[part 1 of 3: package /ARRoot]
AUTOSAR XML (schema 3.1.1)
standard types defined: boolean, uint16, uint8, UInt8, Boolean, UInt16, UInt32
package /ARRoot
  ecu ECM_BODY_ECUType
  ecu instance ECM_BODY: associated-i-pdu-group=[IPDUGroupIN_CAN_HS_BACKBONE, IPDUGroupOUT_CAN_HS_BACKBONE, IPDUGroupIN_CAN_LS_BODY, IPDUGroupOUT_CAN_LS_BODY, IPDUGroupOUT_LIN_UPE_BODY], com-configuration-id=30, com-processing-period=0.01, diagnostic-address=32, pdu-r-configuration-id=31
    can communication controller ctl_CAN_HS_BACKBONE: number-of-samples=0, propagation-delay=0.0, sync-jump-width=0, time-seg-0=3, time-seg-1=1
    can communication controller ctl_CAN_LS_BODY: number-of-samples=0, propagation-delay=0.0, time-seg-0=3, time-seg-1=1
    lin slave ctl_LIN_UPE_BODY
    communication connector cc_CAN_HS_BACKBONE: channel=CAN_HS_BACKBONE, comm-controller=ctl_CAN_HS_BACKBONE
    communication connector cc_CAN_LS_BODY: channel=CAN_LS_BODY, comm-controller=ctl_CAN_LS_BODY
    communication connector cc_LIN_UPE_BODY: channel=LIN_UPE_BODY, comm-controller=ctl_LIN_UPE_BODY
  can cluster CAN_HS_BACKBONE_CANBus: protocol-name=CAN, speed=500000
    physical channel CAN_HS_BACKBONE
      frame BB_BODY_432: id 0x432, from ECM_BODY, frame-length=6, can-addressing-mode=STANDARD
        pdu ipdu_BB_BODY_432: length=48, cyclic-timing={repeating-time=0.05, starting-time=0.05}
          signal i_REVEIL_PRINCIPAL_N1: start 6, 2 bit, little-endian, data-type=t_REVEIL_PRINCIPAL, init-value=init_REVEIL_PRINCIPAL, update-indication-bit-position=6
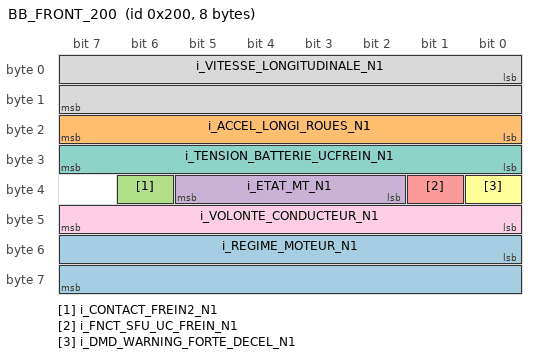
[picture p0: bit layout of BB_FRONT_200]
      frame BB_FRONT_200: id 0x200, to ECM_BODY, frame-length=8, can-addressing-mode=STANDARD
        pdu ipdu_BB_FRONT_200: length=64, cyclic-timing={repeating-time=0.01, starting-time=0.01}
          signal i_REGIME_MOTEUR_N1: start 48, 16 bit, little-endian, data-type=t_REGIME_MOTEUR, init-value=init_REGIME_MOTEUR, update-indication-bit-position=48, to ECM_BODY
          signal i_ACCEL_LONGI_ROUES_N1: start 16, 8 bit, little-endian, data-type=t_ACCEL_LONGI_ROUES, init-value=init_ACCEL_LONGI_ROUES, update-indication-bit-position=16, to ECM_BODY
          signal i_CONTACT_FREIN2_N1: start 38, 1 bit, little-endian, data-type=ARRoot/boolean, init-value=init_CONTACT_FREIN2, update-indication-bit-position=38, to ECM_BODY
          signal i_ETAT_MT_N1: start 34, 4 bit, little-endian, data-type=uint4, init-value=init_ETAT_MT, update-indication-bit-position=34, to ECM_BODY
          signal i_FNCT_SFU_UC_FREIN_N1: start 33, 1 bit, little-endian, data-type=ARRoot/boolean, init-value=init_FNCT_SFU_UC_FREIN, update-indication-bit-position=33, to ECM_BODY
          signal i_DMD_WARNING_FORTE_DECEL_N1: start 32, 1 bit, little-endian, data-type=ARRoot/boolean, init-value=init_DMD_WARNING_FORTE_DECEL, update-indication-bit-position=32, to ECM_BODY
          signal i_TENSION_BATTERIE_UCFREIN_N1: start 24, 8 bit, little-endian, data-type=t_TENSION_BATTERIE_UCFREIN, init-value=init_TENSION_BATTERIE_UCFREIN, update-indication-bit-position=24, to ECM_BODY
          signal i_VITESSE_LONGITUDINALE_N1: start 0, 16 bit, little-endian, data-type=t_VITESSE_LONGITUDINALE, init-value=init_VITESSE_LONGITUDINALE, update-indication-bit-position=0, to ECM_BODY
          signal i_VOLONTE_CONDUCTEUR_N1: start 40, 8 bit, little-endian, data-type=t_VOLONTE_CONDUCTEUR, init-value=init_VOLONTE_CONDUCTEUR, update-indication-bit-position=40, to ECM_BODY
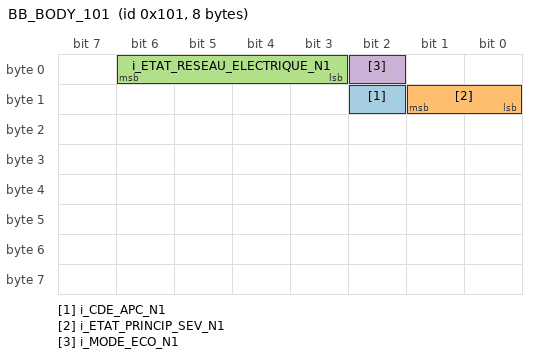
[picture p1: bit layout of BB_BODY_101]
      frame BB_BODY_101: id 0x101, from ECM_BODY, frame-length=8, can-addressing-mode=STANDARD
        pdu ipdu_BB_BODY_101: length=64, cyclic-timing={repeating-time=0.05, starting-time=0.05}
          signal i_CDE_APC_N1: start 10, 1 bit, little-endian, data-type=ARRoot/boolean, init-value=init_CDE_APC, update-indication-bit-position=10
          signal i_ETAT_PRINCIP_SEV_N1: start 8, 2 bit, little-endian, data-type=t_ETAT_PRINCIP_SEV, init-value=init_ETAT_PRINCIP_SEV, update-indication-bit-position=8
          signal i_ETAT_RESEAU_ELECTRIQUE_N1: start 3, 4 bit, little-endian, data-type=t_ETAT_RESEAU_ELECTRIQUE, init-value=init_ETAT_RESEAU_ELECTRIQUE, update-indication-bit-position=3
          signal i_MODE_ECO_N1: start 2, 1 bit, little-endian, data-type=ARRoot/boolean, init-value=init_MODE_ECO, update-indication-bit-position=2
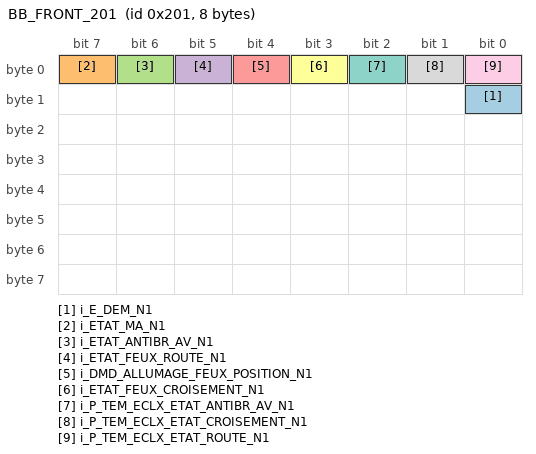
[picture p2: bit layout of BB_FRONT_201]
      frame BB_FRONT_201: id 0x201, to ECM_BODY, frame-length=8, can-addressing-mode=STANDARD
        pdu ipdu_BB_FRONT_201: length=64, cyclic-timing={repeating-time=0.05, starting-time=0.05}
          signal i_E_DEM_N1: start 8, 1 bit, little-endian, data-type=ARRoot/boolean, init-value=init_E_DEM, update-indication-bit-position=8, to ECM_BODY
          signal i_ETAT_MA_N1: start 7, 1 bit, little-endian, data-type=ARRoot/boolean, init-value=init_ETAT_MA, update-indication-bit-position=7, to ECM_BODY
          signal i_ETAT_ANTIBR_AV_N1: start 6, 1 bit, little-endian, data-type=ARRoot/boolean, init-value=init_ETAT_ANTIBR_AV, update-indication-bit-position=6, to ECM_BODY
          signal i_ETAT_FEUX_ROUTE_N1: start 5, 1 bit, little-endian, data-type=ARRoot/boolean, init-value=init_ETAT_FEUX_ROUTE, update-indication-bit-position=5, to ECM_BODY
          signal i_DMD_ALLUMAGE_FEUX_POSITION_N1: start 4, 1 bit, little-endian, data-type=ARRoot/boolean, init-value=init_DMD_ALLUMAGE_FEUX_POSITION, update-indication-bit-position=4, to ECM_BODY
          signal i_ETAT_FEUX_CROISEMENT_N1: start 3, 1 bit, little-endian, data-type=ARRoot/boolean, init-value=init_ETAT_FEUX_CROISEMENT, update-indication-bit-position=3, to ECM_BODY
          signal i_P_TEM_ECLX_ETAT_ANTIBR_AV_N1: start 2, 1 bit, little-endian, data-type=ARRoot/boolean, init-value=init_P_TEM_ECLX_ETAT_ANTIBR_AV, update-indication-bit-position=2, to ECM_BODY
          signal i_P_TEM_ECLX_ETAT_CROISEMENT_N1: start 1, 1 bit, little-endian, data-type=ARRoot/boolean, init-value=init_P_TEM_ECLX_ETAT_CROISEMENT, update-indication-bit-position=1, to ECM_BODY
          signal i_P_TEM_ECLX_ETAT_ROUTE_N1: start 0, 1 bit, little-endian, data-type=ARRoot/boolean, init-value=init_P_TEM_ECLX_ETAT_ROUTE, update-indication-bit-position=0, to ECM_BODY
      frame BB_BODY_100: id 0x100, from ECM_BODY, frame-length=8, can-addressing-mode=STANDARD
        pdu ipdu_BB_BODY_100: length=64, cyclic-timing={repeating-time=0.05, starting-time=0.05}
          signal i_PILOTAGE_FEUX_POSITION_AVG_N1: start 22, 1 bit, little-endian, data-type=ARRoot/boolean, init-value=init_PILOTAGE_FEUX_POSITION_AVG, update-indication-bit-position=22
          signal i_PILOTAGE_FEUX_POSITION_AVD_N1: start 23, 1 bit, little-endian, data-type=ARRoot/boolean, init-value=init_PILOTAGE_FEUX_POSITION_AVD, update-indication-bit-position=23
          signal i_CMD_FEUX_POSITION_AR_N1: start 21, 1 bit, little-endian, data-type=ARRoot/boolean, init-value=init_CMD_FEUX_POSITION_AR, update-indication-bit-position=21
          signal i_TYPE_REVEIL_BAGUE_ECLAIRAGE_N1: start 20, 1 bit, little-endian, data-type=ARRoot/boolean, init-value=init_TYPE_REVEIL_BAGUE_ECLAIRAGE, update-indication-bit-position=20
          signal i_CMD_FEUX_STOP_N1: start 19, 1 bit, little-endian, data-type=ARRoot/boolean, init-value=init_CMD_FEUX_STOP, update-indication-bit-position=19
          signal i_CMD_FEUX_MAR_N1: start 18, 1 bit, little-endian, data-type=ARRoot/boolean, init-value=init_CMD_FEUX_MAR, update-indication-bit-position=18
          signal i_CMD_ANTIBR_AR_N1: start 17, 1 bit, little-endian, data-type=ARRoot/boolean, init-value=init_CMD_ANTIBR_AR, update-indication-bit-position=17
          signal i_PILOTAGE_FEU_DIURNE_DEDIE_G_N1: start 16, 1 bit, little-endian, data-type=ARRoot/boolean, init-value=init_PILOTAGE_FEU_DIURNE_DEDIE_G, update-indication-bit-position=16
          signal i_PILOTAGE_FEU_DIURNE_DEDIE_D_N1: start 15, 1 bit, little-endian, data-type=ARRoot/boolean, init-value=init_PILOTAGE_FEU_DIURNE_DEDIE_D, update-indication-bit-position=15
          signal i_CMD_AVER_SONORE_N1: start 14, 1 bit, little-endian, data-type=ARRoot/boolean, init-value=init_CMD_AVER_SONORE, update-indication-bit-position=14
          signal DMD_ANTIBROUILLARD0_IS: start 11, 2 bit, little-endian, data-type=t_DMD_ANTIBROUILLARD, init-value=init_DMD_ANTIBROUILLARD, update-indication-bit-position=11
          signal i_DMD_FEUX_CROISEMENT_AAF_N1: start 10, 1 bit, little-endian, data-type=ARRoot/boolean, init-value=init_DMD_FEUX_CROISEMENT_AAF, update-indication-bit-position=10
          signal i_DMD_ALLUMAGE_FEUX_CROISEMENT_N1: start 9, 1 bit, little-endian, data-type=ARRoot/boolean, init-value=init_DMD_ALLUMAGE_FEUX_CROISEMENT, update-indication-bit-position=9
          signal i_DMD_LOCAL_TELECMD_N1: start 8, 1 bit, little-endian, data-type=ARRoot/boolean, init-value=init_DMD_LOCAL_TELECMD, update-indication-bit-position=8
          signal i_ETAT_ANTIBR_AR_N1: start 7, 1 bit, little-endian, data-type=ARRoot/boolean, init-value=init_ETAT_ANTIBR_AR, update-indication-bit-position=7
          signal i_ETAT_FEUX_DIURNES_N1: start 6, 1 bit, little-endian, data-type=ARRoot/boolean, init-value=init_ETAT_FEUX_DIURNES, update-indication-bit-position=6
          signal i_ETAT_FEUX_POSITION_N1: start 5, 1 bit, little-endian, data-type=ARRoot/boolean, init-value=init_ETAT_FEUX_POSITION, update-indication-bit-position=5
          signal i_ETAT_CMD_ECLAIRAGE_N1: start 0, 4 bit, little-endian, data-type=t_ETAT_CMD_ECLAIRAGE, init-value=init_ETAT_CMD_ECLAIRAGE, update-indication-bit-position=0
  integer type t_REVEIL_PRINCIPAL: lower-limit=0, upper-limit=3
  constant specification cst_init_REVEIL_PRINCIPAL
    value:
      integer literal init_REVEIL_PRINCIPAL: type=t_REVEIL_PRINCIPAL, value=0
  integer type t_REGIME_MOTEUR: lower-limit=0, upper-limit=65534
  constant specification cst_init_REGIME_MOTEUR
    value:
      integer literal init_REGIME_MOTEUR: type=t_REGIME_MOTEUR, value=0
  integer type t_ACCEL_LONGI_ROUES: lower-limit=0, upper-limit=254
  constant specification cst_init_ACCEL_LONGI_ROUES
    value:
      integer literal init_ACCEL_LONGI_ROUES: type=t_ACCEL_LONGI_ROUES, value=0
  constant specification cst_init_CONTACT_FREIN2
    value:
      boolean literal init_CONTACT_FREIN2: type=ARRoot/boolean, value=false
  integer type uint4: lower-limit=0, upper-limit=16
  constant specification cst_init_ETAT_MT
    value:
      integer literal init_ETAT_MT: type=uint4, value=0
  constant specification cst_init_FNCT_SFU_UC_FREIN
    value:
      boolean literal init_FNCT_SFU_UC_FREIN: type=ARRoot/boolean, value=false
  constant specification cst_init_DMD_WARNING_FORTE_DECEL
    value:
      boolean literal init_DMD_WARNING_FORTE_DECEL: type=ARRoot/boolean, value=false
  integer type t_TENSION_BATTERIE_UCFREIN: lower-limit=0, upper-limit=230
  constant specification cst_init_TENSION_BATTERIE_UCFREIN
    value:
      integer literal init_TENSION_BATTERIE_UCFREIN: type=t_TENSION_BATTERIE_UCFREIN, value=0
  integer type t_VITESSE_LONGITUDINALE: lower-limit=0, upper-limit=65534
  constant specification cst_init_VITESSE_LONGITUDINALE
    value:
      integer literal init_VITESSE_LONGITUDINALE: type=t_VITESSE_LONGITUDINALE, value=0
  integer type t_VOLONTE_CONDUCTEUR: lower-limit=0, upper-limit=100
  constant specification cst_init_VOLONTE_CONDUCTEUR
    value:
      integer literal init_VOLONTE_CONDUCTEUR: type=t_VOLONTE_CONDUCTEUR, value=0
  constant specification cst_init_CDE_APC
    value:
      boolean literal init_CDE_APC: type=ARRoot/boolean, value=false
  integer type t_ETAT_PRINCIP_SEV: lower-limit=0, upper-limit=2
  constant specification cst_init_ETAT_PRINCIP_SEV
    value:
      integer literal init_ETAT_PRINCIP_SEV: type=t_ETAT_PRINCIP_SEV, value=0
  integer type t_ETAT_RESEAU_ELECTRIQUE: lower-limit=0, upper-limit=8
  constant specification cst_init_ETAT_RESEAU_ELECTRIQUE
    value:
      integer literal init_ETAT_RESEAU_ELECTRIQUE: type=t_ETAT_RESEAU_ELECTRIQUE, value=0
  constant specification cst_init_MODE_ECO
    value:
      boolean literal init_MODE_ECO: type=ARRoot/boolean, value=false
  constant specification cst_init_E_DEM
    value:
      boolean literal init_E_DEM: type=ARRoot/boolean, value=false
  constant specification cst_init_ETAT_MA
    value:
      boolean literal init_ETAT_MA: type=ARRoot/boolean, value=false
  constant specification cst_init_ETAT_ANTIBR_AV
    value:
      boolean literal init_ETAT_ANTIBR_AV: type=ARRoot/boolean, value=false
  constant specification cst_init_ETAT_FEUX_ROUTE
    value:
      boolean literal init_ETAT_FEUX_ROUTE: type=ARRoot/boolean, value=false
  constant specification cst_init_DMD_ALLUMAGE_FEUX_POSITION
    value:
      boolean literal init_DMD_ALLUMAGE_FEUX_POSITION: type=ARRoot/boolean, value=false
  constant specification cst_init_ETAT_FEUX_CROISEMENT
    value:
      boolean literal init_ETAT_FEUX_CROISEMENT: type=ARRoot/boolean, value=false
  constant specification cst_init_P_TEM_ECLX_ETAT_ANTIBR_AV
    value:
      boolean literal init_P_TEM_ECLX_ETAT_ANTIBR_AV: type=ARRoot/boolean, value=false
  constant specification cst_init_P_TEM_ECLX_ETAT_CROISEMENT
    value:
      boolean literal init_P_TEM_ECLX_ETAT_CROISEMENT: type=ARRoot/boolean, value=false
  constant specification cst_init_P_TEM_ECLX_ETAT_ROUTE
    value:
      boolean literal init_P_TEM_ECLX_ETAT_ROUTE: type=ARRoot/boolean, value=false
  constant specification cst_init_PILOTAGE_FEUX_POSITION_AVG
    value:
      boolean literal init_PILOTAGE_FEUX_POSITION_AVG: type=ARRoot/boolean, value=false
  constant specification cst_init_PILOTAGE_FEUX_POSITION_AVD
    value:
      boolean literal init_PILOTAGE_FEUX_POSITION_AVD: type=ARRoot/boolean, value=false
  constant specification cst_init_CMD_FEUX_POSITION_AR
    value:
      boolean literal init_CMD_FEUX_POSITION_AR: type=ARRoot/boolean, value=false
  constant specification cst_init_TYPE_REVEIL_BAGUE_ECLAIRAGE
    value:
      boolean literal init_TYPE_REVEIL_BAGUE_ECLAIRAGE: type=ARRoot/boolean, value=false
  constant specification cst_init_CMD_FEUX_STOP
    value:
      boolean literal init_CMD_FEUX_STOP: type=ARRoot/boolean, value=false
  constant specification cst_init_CMD_FEUX_MAR
    value:
      boolean literal init_CMD_FEUX_MAR: type=ARRoot/boolean, value=false
  constant specification cst_init_CMD_ANTIBR_AR
    value:
      boolean literal init_CMD_ANTIBR_AR: type=ARRoot/boolean, value=false
  constant specification cst_init_PILOTAGE_FEU_DIURNE_DEDIE_G
    value:
      boolean literal init_PILOTAGE_FEU_DIURNE_DEDIE_G: type=ARRoot/boolean, value=false
  constant specification cst_init_PILOTAGE_FEU_DIURNE_DEDIE_D
    value:
      boolean literal init_PILOTAGE_FEU_DIURNE_DEDIE_D: type=ARRoot/boolean, value=false
  constant specification cst_init_CMD_AVER_SONORE
    value:
      boolean literal init_CMD_AVER_SONORE: type=ARRoot/boolean, value=false
  integer type t_DMD_ANTIBROUILLARD: lower-limit=0, upper-limit=2
  constant specification cst_init_DMD_ANTIBROUILLARD
    value:
      integer literal init_DMD_ANTIBROUILLARD: type=t_DMD_ANTIBROUILLARD, value=0
  constant specification cst_init_DMD_FEUX_CROISEMENT_AAF
    value:
      boolean literal init_DMD_FEUX_CROISEMENT_AAF: type=ARRoot/boolean, value=false
  constant specification cst_init_DMD_ALLUMAGE_FEUX_CROISEMENT
    value:
      boolean literal init_DMD_ALLUMAGE_FEUX_CROISEMENT: type=ARRoot/boolean, value=false
  constant specification cst_init_DMD_LOCAL_TELECMD
    value:
      boolean literal init_DMD_LOCAL_TELECMD: type=ARRoot/boolean, value=false
  constant specification cst_init_ETAT_ANTIBR_AR
    value:
      boolean literal init_ETAT_ANTIBR_AR: type=ARRoot/boolean, value=false
  constant specification cst_init_ETAT_FEUX_DIURNES
    value:
      boolean literal init_ETAT_FEUX_DIURNES: type=ARRoot/boolean, value=false
  constant specification cst_init_ETAT_FEUX_POSITION
    value:
      boolean literal init_ETAT_FEUX_POSITION: type=ARRoot/boolean, value=false
  integer type t_ETAT_CMD_ECLAIRAGE: lower-limit=0, upper-limit=8
  constant specification cst_init_ETAT_CMD_ECLAIRAGE
    value:
      integer literal init_ETAT_CMD_ECLAIRAGE: type=t_ETAT_CMD_ECLAIRAGE, value=0
  can cluster CAN_LS_BODY_CANBus: protocol-name=CAN, speed=125000
    physical channel CAN_LS_BODY
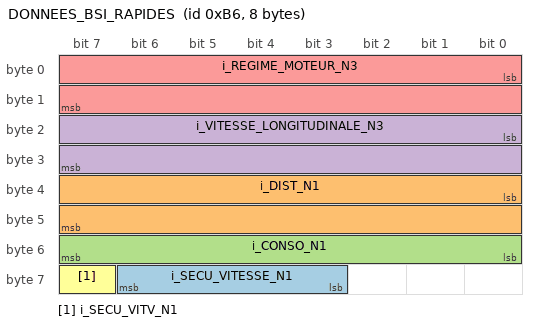
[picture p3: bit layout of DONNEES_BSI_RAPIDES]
      frame DONNEES_BSI_RAPIDES: id 0xB6, from ECM_BODY, frame-length=8, can-addressing-mode=STANDARD
        pdu ipdu_DONNEES_BSI_RAPIDES: length=64, cyclic-timing={repeating-time=0.05, starting-time=0.05}
          signal i_SECU_VITESSE_N1: start 59, 4 bit, little-endian, data-type=uint4, init-value=init_SECU_VITESSE, update-indication-bit-position=59
          signal i_DIST_N1: start 32, 16 bit, little-endian, data-type=uint16, init-value=init_DIST, update-indication-bit-position=32
          signal i_CONSO_N1: start 48, 8 bit, little-endian, data-type=uint8, init-value=init_CONSO, update-indication-bit-position=48
          signal i_VITESSE_LONGITUDINALE_N3: start 16, 16 bit, little-endian, data-type=t_VITESSE_LONGITUDINALE, init-value=init_VITESSE_LONGITUDINALE, update-indication-bit-position=16
          signal i_REGIME_MOTEUR_N3: start 0, 16 bit, little-endian, data-type=t_REGIME_MOTEUR, init-value=init_REGIME_MOTEUR, update-indication-bit-position=0
          signal i_SECU_VITV_N1: start 63, 1 bit, little-endian, data-type=ARRoot/boolean, init-value=init_SECU_VITV, update-indication-bit-position=63
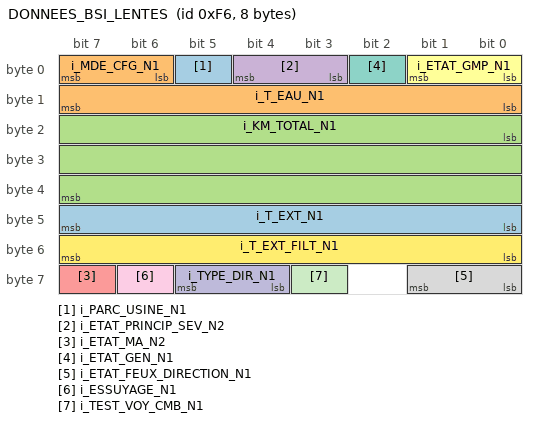
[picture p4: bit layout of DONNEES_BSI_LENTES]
      frame DONNEES_BSI_LENTES: id 0xF6, from ECM_BODY, frame-length=8, can-addressing-mode=STANDARD
        pdu ipdu_DONNEES_BSI_LENTES: length=64, cyclic-timing={repeating-time=0.5, starting-time=0.5}
          signal i_PARC_USINE_N1: start 5, 1 bit, little-endian, data-type=ARRoot/boolean, init-value=init_PARC_USINE, update-indication-bit-position=5
          signal i_MDE_CFG_N1: start 6, 2 bit, little-endian, data-type=uint2, init-value=init_MDE_CFG, update-indication-bit-position=6
          signal i_KM_TOTAL_N1: start 16, 24 bit, little-endian, data-type=t_KM_TOTAL, init-value=init_KM_TOTAL, update-indication-bit-position=16
          signal i_ETAT_PRINCIP_SEV_N2: start 3, 2 bit, little-endian, data-type=t_ETAT_PRINCIP_SEV, init-value=init_ETAT_PRINCIP_SEV, update-indication-bit-position=3
          signal i_ETAT_MA_N2: start 63, 1 bit, little-endian, data-type=ARRoot/boolean, init-value=init_ETAT_MA, update-indication-bit-position=63
          signal i_ETAT_GMP_N1: start 0, 2 bit, little-endian, data-type=uint2, init-value=init_ETAT_GMP, update-indication-bit-position=0
          signal i_ETAT_GEN_N1: start 2, 1 bit, little-endian, data-type=ARRoot/boolean, init-value=init_ETAT_GEN, update-indication-bit-position=2
          signal i_ETAT_FEUX_DIRECTION_N1: start 56, 2 bit, little-endian, data-type=uint2, init-value=init_ETAT_FEUX_DIRECTION, update-indication-bit-position=56
          signal i_ESSUYAGE_N1: start 62, 1 bit, little-endian, data-type=ARRoot/boolean, init-value=init_ESSUYAGE, update-indication-bit-position=62
          signal i_TYPE_DIR_N1: start 60, 2 bit, little-endian, data-type=uint2, init-value=init_TYPE_DIR, update-indication-bit-position=60
          signal i_TEST_VOY_CMB_N1: start 59, 1 bit, little-endian, data-type=ARRoot/boolean, init-value=init_TEST_VOY_CMB, update-indication-bit-position=59
          signal i_T_EXT_FILT_N1: start 48, 8 bit, little-endian, data-type=t_T_EXT_FILT, init-value=init_T_EXT_FILT, update-indication-bit-position=48
          signal i_T_EXT_N1: start 40, 8 bit, little-endian, data-type=t_T_EXT, init-value=init_T_EXT, update-indication-bit-position=40
          signal i_T_EAU_N1: start 8, 8 bit, little-endian, data-type=t_T_EAU, init-value=init_T_EAU, update-indication-bit-position=8
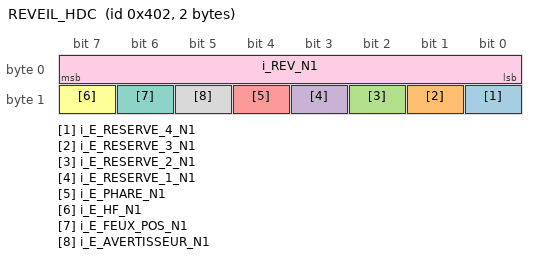
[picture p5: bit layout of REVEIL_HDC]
      frame REVEIL_HDC: id 0x402, to ECM_BODY, frame-length=2, can-addressing-mode=STANDARD
        pdu ipdu_REVEIL_HDC: length=16, cyclic-timing={repeating-time=0.01, starting-time=0.01}, event-controlled-timing=debounce-time=0.0
          signal i_E_RESERVE_4_N1: start 8, 1 bit, little-endian, data-type=ARRoot/boolean, init-value=init_E_RESERVE_4, update-indication-bit-position=8, to ECM_BODY
          signal i_E_RESERVE_3_N1: start 9, 1 bit, little-endian, data-type=ARRoot/boolean, init-value=init_E_RESERVE_3, update-indication-bit-position=9, to ECM_BODY
          signal i_E_RESERVE_2_N1: start 10, 1 bit, little-endian, data-type=ARRoot/boolean, init-value=init_E_RESERVE_2, update-indication-bit-position=10, to ECM_BODY
          signal i_E_RESERVE_1_N1: start 11, 1 bit, little-endian, data-type=ARRoot/boolean, init-value=init_E_RESERVE_1, update-indication-bit-position=11, to ECM_BODY
          signal i_E_PHARE_N1: start 12, 1 bit, little-endian, data-type=ARRoot/boolean, init-value=init_E_PHARE, update-indication-bit-position=12, to ECM_BODY
          signal i_E_HF_N1: start 15, 1 bit, little-endian, data-type=ARRoot/boolean, init-value=init_E_HF, update-indication-bit-position=15, to ECM_BODY
          signal i_E_FEUX_POS_N1: start 14, 1 bit, little-endian, data-type=ARRoot/boolean, init-value=init_E_FEUX_POS, update-indication-bit-position=14, to ECM_BODY
          signal i_E_AVERTISSEUR_N1: start 13, 1 bit, little-endian, data-type=ARRoot/boolean, init-value=init_E_AVERTISSEUR, update-indication-bit-position=13, to ECM_BODY
          signal i_REV_N1: start 0, 8 bit, little-endian, data-type=uint8, init-value=init_REV, update-indication-bit-position=0, to ECM_BODY
      frame COMMANDE_BRT: id 0x102, from ECM_BODY, frame-length=2, can-addressing-mode=STANDARD
        pdu ipdu_COMMANDE_BRT: length=16, event-controlled-timing=debounce-time=0.0
          signal i_NIV_SON_CMD_BRT_N1: start 8, 8 bit, little-endian, data-type=t_NIV_SON_CMD_BRT, init-value=init_NIV_SON_CMD_BRT, update-indication-bit-position=8
          signal i_EM_SON_CMD_BRT_N1: start 0, 4 bit, little-endian, data-type=t_EM_SON_CMD_BRT, init-value=init_EM_SON_CMD_BRT, update-indication-bit-position=0
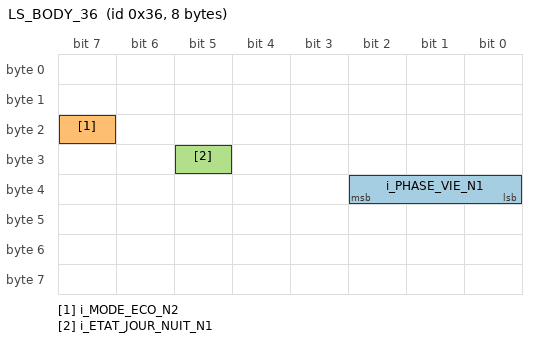
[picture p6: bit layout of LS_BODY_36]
      frame LS_BODY_36: id 0x36, from ECM_BODY, frame-length=8, can-addressing-mode=STANDARD
        pdu ipdu_LS_BODY_36: length=64, cyclic-timing={repeating-time=0.1, starting-time=0.1}, event-controlled-timing=debounce-time=0.0
          signal i_PHASE_VIE_N1: start 32, 3 bit, little-endian, data-type=t_PHASE_VIE, init-value=init_PHASE_VIE, update-indication-bit-position=32
          signal i_MODE_ECO_N2: start 23, 1 bit, little-endian, data-type=ARRoot/boolean, init-value=init_MODE_ECO, update-indication-bit-position=23
          signal i_ETAT_JOUR_NUIT_N1: start 29, 1 bit, little-endian, data-type=ARRoot/boolean, init-value=init_ETAT_JOUR_NUIT, update-indication-bit-position=29
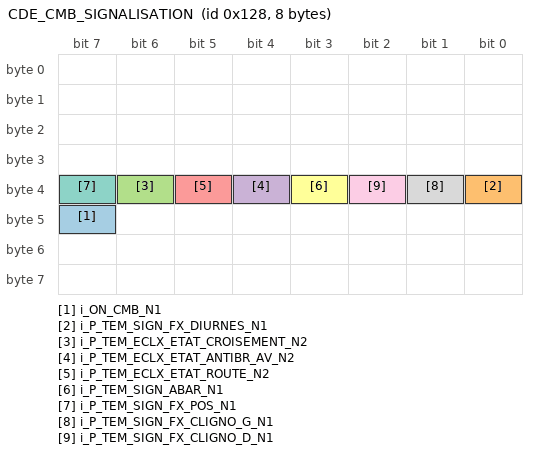
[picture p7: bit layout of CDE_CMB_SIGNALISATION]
      frame CDE_CMB_SIGNALISATION: id 0x128, from ECM_BODY, frame-length=8, can-addressing-mode=STANDARD
        pdu ipdu_CDE_CMB_SIGNALISATION: length=64, cyclic-timing={repeating-time=0.2, starting-time=0.2}, event-controlled-timing=debounce-time=0.0
          signal i_ON_CMB_N1: start 47, 1 bit, little-endian, data-type=ARRoot/boolean, init-value=init_ON_CMB, update-indication-bit-position=47
          signal i_P_TEM_SIGN_FX_DIURNES_N1: start 32, 1 bit, little-endian, data-type=ARRoot/boolean, init-value=init_P_TEM_SIGN_FX_DIURNES, update-indication-bit-position=32
          signal i_P_TEM_ECLX_ETAT_CROISEMENT_N2: start 38, 1 bit, little-endian, data-type=ARRoot/boolean, init-value=init_P_TEM_ECLX_ETAT_CROISEMENT, update-indication-bit-position=38
          signal i_P_TEM_ECLX_ETAT_ANTIBR_AV_N2: start 36, 1 bit, little-endian, data-type=ARRoot/boolean, init-value=init_P_TEM_ECLX_ETAT_ANTIBR_AV, update-indication-bit-position=36
          signal i_P_TEM_ECLX_ETAT_ROUTE_N2: start 37, 1 bit, little-endian, data-type=ARRoot/boolean, init-value=init_P_TEM_ECLX_ETAT_ROUTE, update-indication-bit-position=37
          signal i_P_TEM_SIGN_ABAR_N1: start 35, 1 bit, little-endian, system signal P_TEM_SIGN_FX_ABAR, data-type=ARRoot/boolean, init-value=init_P_TEM_SIGN_ABAR, update-indication-bit-position=35
          signal i_P_TEM_SIGN_FX_POS_N1: start 39, 1 bit, little-endian, data-type=ARRoot/boolean, init-value=init_P_TEM_SIGN_FX_POS, update-indication-bit-position=39
          signal i_P_TEM_SIGN_FX_CLIGNO_G_N1: start 33, 1 bit, little-endian, data-type=ARRoot/boolean, init-value=init_P_TEM_SIGN_FX_CLIGNO_G, update-indication-bit-position=33
          signal i_P_TEM_SIGN_FX_CLIGNO_D_N1: start 34, 1 bit, little-endian, data-type=ARRoot/boolean, init-value=init_P_TEM_SIGN_FX_CLIGNO_D, update-indication-bit-position=34
      frame ETAT_BDCP: id 0x184, to ECM_BODY, frame-length=1, can-addressing-mode=STANDARD
        pdu ipdu_ETAT_BDCP: length=8, cyclic-timing={repeating-time=0.2, starting-time=0.2}, event-controlled-timing=debounce-time=0.0
          signal i_INFO_CHOC_PIETON_N1: start 4, 1 bit, little-endian, data-type=ARRoot/boolean, init-value=init_INFO_CHOC_PIETON, update-indication-bit-position=4, to ECM_BODY
          signal i_CHOC_FEUX_DET_N1: start 0, 1 bit, little-endian, data-type=ARRoot/boolean, init-value=init_CHOC_FEUX_DET, update-indication-bit-position=0, to ECM_BODY
      frame ETAT_CDPL_RAPIDES: id 0x5A, to ECM_BODY, frame-length=2, can-addressing-mode=STANDARD
        pdu ipdu_ETAT_CDPL_RAPIDES: length=16, cyclic-timing={repeating-time=0.1, starting-time=0.1}
          signal i_DMD_FEUX_CROISEMENT_AAF_N2: start 0, 1 bit, little-endian, data-type=ARRoot/boolean, init-value=init_DMD_FEUX_CROISEMENT_AAF, update-indication-bit-position=0, to ECM_BODY
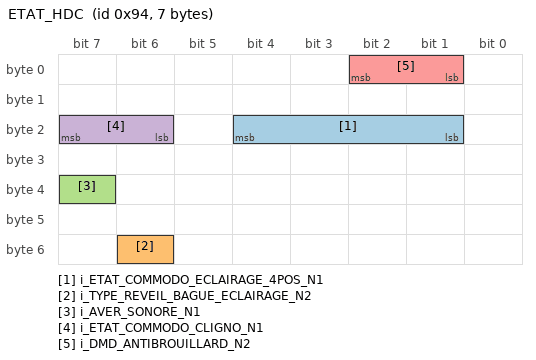
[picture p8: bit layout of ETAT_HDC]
      frame ETAT_HDC: id 0x94, to ECM_BODY, frame-length=7, can-addressing-mode=STANDARD
        pdu ipdu_ETAT_HDC: length=56, cyclic-timing={repeating-time=0.1, starting-time=0.1}, event-controlled-timing=debounce-time=0.0
          signal i_ETAT_COMMODO_ECLAIRAGE_4POS_N1: start 17, 4 bit, little-endian, data-type=t_ETAT_COMMODO_ECLAIRAGE_4POS, init-value=init_ETAT_COMMODO_ECLAIRAGE_4POS, update-indication-bit-position=17, to ECM_BODY
          signal i_TYPE_REVEIL_BAGUE_ECLAIRAGE_N2: start 54, 1 bit, little-endian, data-type=ARRoot/boolean, init-value=init_TYPE_REVEIL_BAGUE_ECLAIRAGE, update-indication-bit-position=54, to ECM_BODY
          signal i_AVER_SONORE_N1: start 39, 1 bit, little-endian, data-type=ARRoot/boolean, init-value=init_AVER_SONORE, update-indication-bit-position=39, to ECM_BODY
          signal i_ETAT_COMMODO_CLIGNO_N1: start 22, 2 bit, little-endian, data-type=t_ETAT_COMMODO_CLIGNO, init-value=init_ETAT_COMMODO_CLIGNO, update-indication-bit-position=22, to ECM_BODY
          signal i_DMD_ANTIBROUILLARD_N2: start 1, 2 bit, little-endian, system signal ETAT_DMD_ANTIBROUILLARD, data-type=t_DMD_ANTIBROUILLARD, init-value=init_DMD_ANTIBROUILLARD, update-indication-bit-position=1, to ECM_BODY
  constant specification cst_init_SECU_VITESSE
    value:
      integer literal init_SECU_VITESSE: type=uint4, value=5
  constant specification cst_init_DIST
    value:
      integer literal init_DIST: type=uint16, value=0
  constant specification cst_init_CONSO
    value:
      integer literal init_CONSO: type=uint8, value=0
  constant specification cst_init_SECU_VITV
    value:
      boolean literal init_SECU_VITV: type=ARRoot/boolean, value=true
  constant specification cst_init_PARC_USINE
    value:
      boolean literal init_PARC_USINE: type=ARRoot/boolean, value=false
  integer type uint2: lower-limit=0, upper-limit=4
  constant specification cst_init_MDE_CFG
    value:
      integer literal init_MDE_CFG: type=uint2, value=2
  real type t_KM_TOTAL: lower-limit=0, upper-limit=16777214, encoding=SINGLE
  constant specification cst_init_KM_TOTAL
    value:
      real literal init_KM_TOTAL: type=t_KM_TOTAL, value=0.0
  constant specification cst_init_ETAT_GMP
    value:
      integer literal init_ETAT_GMP: type=uint2, value=0
  constant specification cst_init_ETAT_GEN
    value:
      boolean literal init_ETAT_GEN: type=ARRoot/boolean, value=false
  constant specification cst_init_ETAT_FEUX_DIRECTION
    value:
      integer literal init_ETAT_FEUX_DIRECTION: type=uint2, value=0
  constant specification cst_init_ESSUYAGE
    value:
      boolean literal init_ESSUYAGE: type=ARRoot/boolean, value=false
  constant specification cst_init_TYPE_DIR
    value:
      integer literal init_TYPE_DIR: type=uint2, value=2
  constant specification cst_init_TEST_VOY_CMB
    value:
      boolean literal init_TEST_VOY_CMB: type=ARRoot/boolean, value=false
  integer type t_T_EXT_FILT: lower-limit=0, upper-limit=250
  constant specification cst_init_T_EXT_FILT
    value:
      integer literal init_T_EXT_FILT: type=t_T_EXT_FILT, value=90
  integer type t_T_EXT: lower-limit=0, upper-limit=250
  constant specification cst_init_T_EXT
    value:
      integer literal init_T_EXT: type=t_T_EXT, value=90
  integer type t_T_EAU: lower-limit=0, upper-limit=250
  constant specification cst_init_T_EAU
    value:
      integer literal init_T_EAU: type=t_T_EAU, value=130
  constant specification cst_init_E_RESERVE_4
    value:
      boolean literal init_E_RESERVE_4: type=ARRoot/boolean, value=false
  constant specification cst_init_E_RESERVE_3
    value:
      boolean literal init_E_RESERVE_3: type=ARRoot/boolean, value=false
  constant specification cst_init_E_RESERVE_2
    value:
      boolean literal init_E_RESERVE_2: type=ARRoot/boolean, value=false
  constant specification cst_init_E_RESERVE_1
    value:
      boolean literal init_E_RESERVE_1: type=ARRoot/boolean, value=false
  constant specification cst_init_E_PHARE
    value:
      boolean literal init_E_PHARE: type=ARRoot/boolean, value=false
  constant specification cst_init_E_HF
    value:
      boolean literal init_E_HF: type=ARRoot/boolean, value=false
  constant specification cst_init_E_FEUX_POS
    value:
      boolean literal init_E_FEUX_POS: type=ARRoot/boolean, value=false
  constant specification cst_init_E_AVERTISSEUR
    value:
      boolean literal init_E_AVERTISSEUR: type=ARRoot/boolean, value=false
  constant specification cst_init_REV
    value:
      integer literal init_REV: type=uint8, value=0
  integer type t_NIV_SON_CMD_BRT: lower-limit=0, upper-limit=255
  constant specification cst_init_NIV_SON_CMD_BRT
    value:
      integer literal init_NIV_SON_CMD_BRT: type=t_NIV_SON_CMD_BRT, value=0
  integer type t_EM_SON_CMD_BRT: lower-limit=0, upper-limit=15
  constant specification cst_init_EM_SON_CMD_BRT
    value:
      integer literal init_EM_SON_CMD_BRT: type=t_EM_SON_CMD_BRT, value=0
  integer type t_PHASE_VIE: lower-limit=0, upper-limit=7
  constant specification cst_init_PHASE_VIE
    value:
      integer literal init_PHASE_VIE: type=t_PHASE_VIE, value=0
  constant specification cst_init_ETAT_JOUR_NUIT
    value:
      boolean literal init_ETAT_JOUR_NUIT: type=ARRoot/boolean, value=false
  constant specification cst_init_ON_CMB
    value:
      boolean literal init_ON_CMB: type=ARRoot/boolean, value=false
  constant specification cst_init_P_TEM_SIGN_FX_DIURNES
    value:
      boolean literal init_P_TEM_SIGN_FX_DIURNES: type=ARRoot/boolean, value=false
  constant specification cst_init_P_TEM_SIGN_ABAR
    value:
      boolean literal init_P_TEM_SIGN_ABAR: type=ARRoot/boolean, value=false
  constant specification cst_init_P_TEM_SIGN_FX_POS
    value:
      boolean literal init_P_TEM_SIGN_FX_POS: type=ARRoot/boolean, value=false
  constant specification cst_init_P_TEM_SIGN_FX_CLIGNO_G
    value:
      boolean literal init_P_TEM_SIGN_FX_CLIGNO_G: type=ARRoot/boolean, value=false
  constant specification cst_init_P_TEM_SIGN_FX_CLIGNO_D
    value:
      boolean literal init_P_TEM_SIGN_FX_CLIGNO_D: type=ARRoot/boolean, value=false
  constant specification cst_init_INFO_CHOC_PIETON
    value:
      boolean literal init_INFO_CHOC_PIETON: type=ARRoot/boolean, value=false
  constant specification cst_init_CHOC_FEUX_DET
    value:
      boolean literal init_CHOC_FEUX_DET: type=ARRoot/boolean, value=false
  integer type t_ETAT_COMMODO_ECLAIRAGE_4POS: lower-limit=0, upper-limit=15
  constant specification cst_init_ETAT_COMMODO_ECLAIRAGE_4POS
    value:
      integer literal init_ETAT_COMMODO_ECLAIRAGE_4POS: type=t_ETAT_COMMODO_ECLAIRAGE_4POS, value=0
  constant specification cst_init_AVER_SONORE
    value:
      boolean literal init_AVER_SONORE: type=ARRoot/boolean, value=false
  integer type t_ETAT_COMMODO_CLIGNO: lower-limit=0, upper-limit=3
  constant specification cst_init_ETAT_COMMODO_CLIGNO
    value:
      integer literal init_ETAT_COMMODO_CLIGNO: type=t_ETAT_COMMODO_CLIGNO, value=0
  lin cluster LIN_UPE_BODY_LINBus: protocol-name=LIN, speed=19200
    physical channel LIN_UPE_BODY
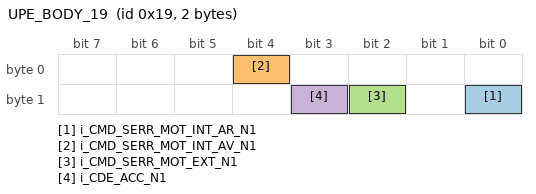
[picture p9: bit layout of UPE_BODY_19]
      frame UPE_BODY_19: id 0x19, from ECM_BODY, frame-length=2, checksum-type=CLASSIC, assign-frame-id-timing{delay=0.0, position-in-table=0, schedule-table=LIN_UPE_BODY_TABLE, assigned-controller=ctl_LIN_UPE_BODY, assigned-frame-triggering=lft_UPE_BODY_19}
        pdu ipdu_UPE_BODY_19: length=16
          signal i_CMD_SERR_MOT_INT_AR_N1: start 8, 1 bit, little-endian, data-type=ARRoot/boolean, init-value=init_CMD_SERR_MOT_INT_AR, update-indication-bit-position=8
          signal i_CMD_SERR_MOT_INT_AV_N1: start 4, 1 bit, little-endian, data-type=ARRoot/boolean, init-value=init_CMD_SERR_MOT_INT_AV, update-indication-bit-position=4
          signal i_CMD_SERR_MOT_EXT_N1: start 10, 1 bit, little-endian, data-type=ARRoot/boolean, init-value=init_CMD_SERR_MOT_EXT, update-indication-bit-position=10
          signal i_CDE_ACC_N1: start 11, 1 bit, little-endian, data-type=ARRoot/boolean, init-value=init_CDE_ACC, update-indication-bit-position=11
    lin schedule table LIN_UPE_BODY_TABLE: priority=255, run-mode=RUN-CONTINUOUS
  constant specification cst_init_CMD_SERR_MOT_INT_AR
    value:
      boolean literal init_CMD_SERR_MOT_INT_AR: type=ARRoot/boolean, value=false
  constant specification cst_init_CMD_SERR_MOT_INT_AV
    value:
      boolean literal init_CMD_SERR_MOT_INT_AV: type=ARRoot/boolean, value=false
  constant specification cst_init_CMD_SERR_MOT_EXT
    value:
      boolean literal init_CMD_SERR_MOT_EXT: type=ARRoot/boolean, value=false
  constant specification cst_init_CDE_ACC
    value:
      boolean literal init_CDE_ACC: type=ARRoot/boolean, value=false
  gateway ECM_BODY_Gateway: ecu=ECM_BODY
    signal-mappings:
      source-signal=ipdu_BB_FRONT_200/ism_REGIME_MOTEUR, target-signal=ipdu_DONNEES_BSI_RAPIDES/ism_REGIME_MOTEUR
      source-signal=ipdu_BB_FRONT_200/ism_VITESSE_LONGITUDINALE, target-signal=ipdu_DONNEES_BSI_RAPIDES/ism_VITESSE_LONGITUDINALE
      source-signal=ipdu_BB_FRONT_201/ism_ETAT_MA, target-signal=ipdu_DONNEES_BSI_LENTES/ism_ETAT_MA
      source-signal=ipdu_BB_FRONT_201/ism_P_TEM_ECLX_ETAT_ANTIBR_AV, target-signal=ipdu_CDE_CMB_SIGNALISATION/ism_P_TEM_ECLX_ETAT_ANTIBR_AV
      source-signal=ipdu_BB_FRONT_201/ism_P_TEM_ECLX_ETAT_CROISEMENT, target-signal=ipdu_CDE_CMB_SIGNALISATION/ism_P_TEM_ECLX_ETAT_CROISEMENT
      source-signal=ipdu_BB_FRONT_201/ism_P_TEM_ECLX_ETAT_ROUTE, target-signal=ipdu_CDE_CMB_SIGNALISATION/ism_P_TEM_ECLX_ETAT_ROUTE
      source-signal=ipdu_ETAT_CDPL_RAPIDES/ism_DMD_FEUX_CROISEMENT_AAF, target-signal=ipdu_BB_BODY_100/ism_DMD_FEUX_CROISEMENT_AAF
      source-signal=ipdu_ETAT_HDC/ism_TYPE_REVEIL_BAGUE_ECLAIRAGE, target-signal=ipdu_BB_BODY_100/ism_TYPE_REVEIL_BAGUE_ECLAIRAGE
      source-signal=ism_ETAT_DMD_ANTIBROUILLARD, target-signal=ism_DMD_ANTIBROUILLARD
  system AEELT: fibex-element=[ECM_BODY_Gateway, CAN_HS_BACKBONE_CANBus, CAN_LS_BODY_CANBus, LIN_UPE_BODY_LINBus]
    mapping AEELTMapping: ecu-mapping{ecu-instance=ECM_BODY, ecu=ECM_BODY_ECUType}
      data-mappings:
        data-element=AEELT_SWC.GERER_AVER_SONORE.SIGNALER_S1.MDL_SIGNALER.SIGNALER.ECM_BODY_SWC.rp_AVER_SONORE.AVER_SONORE, signal=AVER_SONORE
        data-element=AEELT_SWC.GERER_AVER_SONORE.SIGNALER_S1.MDL_SIGNALER.SIGNALER.ECM_BODY_SWC.pp_CMD_AVER_SONORE.CMD_AVER_SONORE, signal=CMD_AVER_SONORE
        data-element=AEELT_SWC.GERER_FX_DIURNES.SIGNALER_S0.MDL_SIGNALER.SIGNALER.ECM_BODY_SWC.rp_DMD_ALLUMAGE_FEUX_POSITION.DMD_ALLUMAGE_FEUX_POSITION, signal=DMD_ALLUMAGE_FEUX_POSITION
        data-element=AEELT_SWC.GERER_FX_DIURNES.SIGNALER_S0.MDL_SIGNALER.SIGNALER.ECM_BODY_SWC.pp_PILOTAGE_FEU_DIURNE_DEDIE_D.PILOTAGE_FEU_DIURNE_DEDIE_D, signal=PILOTAGE_FEU_DIURNE_DEDIE_D
        data-element=AEELT_SWC.GERER_FX_DIURNES.SIGNALER_S0.MDL_SIGNALER.SIGNALER.ECM_BODY_SWC.pp_PILOTAGE_FEU_DIURNE_DEDIE_G.PILOTAGE_FEU_DIURNE_DEDIE_G, signal=PILOTAGE_FEU_DIURNE_DEDIE_G
        data-element=AEELT_SWC.GERER_FX_DIURNES.SIGNALER_S0.MDL_SIGNALER.SIGNALER.ECM_BODY_SWC.pp_ETAT_FEUX_DIURNES.ETAT_FEUX_DIURNES, signal=ETAT_FEUX_DIURNES
        data-element=AEELT_SWC.GERER_FX_DIURNES.SIGNALER_S0.MDL_SIGNALER.SIGNALER.ECM_BODY_SWC.pp_P_TEM_SIGN_FX_DIURNES.P_TEM_SIGN_FX_DIURNES, signal=P_TEM_SIGN_FX_DIURNES
        data-element=AEELT_SWC.CONVERTIR_TENSION_BATTERIE_UCFREIN.GEE_AQEB.MDL_GEE.GEE.ECM_BODY_SWC.rp_TENSION_BATTERIE_UCFREIN.TENSION_BATTERIE_UCFREIN, signal=TENSION_BATTERIE_UCFREIN
        data-element=AEELT_SWC.GERER_PHASE_VIE_CAN_IS.MDL_LPM_BODY.LPM.ECM_BODY_SWC.pp_REVEIL_PRINCIPAL.REVEIL_PRINCIPAL, signal=REVEIL_PRINCIPAL
        data-element=AEELT_SWC.GERER_FX_POS.SIGNALER_S0.MDL_SIGNALER.SIGNALER.ECM_BODY_SWC.rp_ETAT_ANTIBR_AV.ETAT_ANTIBR_AV, signal=ETAT_ANTIBR_AV
        data-element=AEELT_SWC.GERER_FX_POS.SIGNALER_S0.MDL_SIGNALER.SIGNALER.ECM_BODY_SWC.rp_DMD_FEUX_CROISEMENT_AAF.DMD_FEUX_CROISEMENT_AAF, signal=DMD_FEUX_CROISEMENT_AAF
        data-element=AEELT_SWC.GERER_FX_POS.SIGNALER_S0.MDL_SIGNALER.SIGNALER.ECM_BODY_SWC.rp_DMD_ALLUMAGE_FEUX_POSITION.DMD_ALLUMAGE_FEUX_POSITION, signal=DMD_ALLUMAGE_FEUX_POSITION
        data-element=AEELT_SWC.GERER_FX_POS.SIGNALER_S0.MDL_SIGNALER.SIGNALER.ECM_BODY_SWC.rp_VITESSE_LONGITUDINALE.VITESSE_LONGITUDINALE, signal=VITESSE_LONGITUDINALE
        data-element=AEELT_SWC.GERER_FX_POS.SIGNALER_S0.MDL_SIGNALER.SIGNALER.ECM_BODY_SWC.rp_TYPE_REVEIL_BAGUE_ECLAIRAGE.TYPE_REVEIL_BAGUE_ECLAIRAGE, signal=TYPE_REVEIL_BAGUE_ECLAIRAGE
        data-element=AEELT_SWC.GERER_FX_POS.SIGNALER_S0.MDL_SIGNALER.SIGNALER.ECM_BODY_SWC.pp_PILOTAGE_FEUX_POSITION_AVD.PILOTAGE_FEUX_POSITION_AVD, signal=PILOTAGE_FEUX_POSITION_AVD
        data-element=AEELT_SWC.GERER_FX_POS.SIGNALER_S0.MDL_SIGNALER.SIGNALER.ECM_BODY_SWC.pp_PILOTAGE_FEUX_POSITION_AVG.PILOTAGE_FEUX_POSITION_AVG, signal=PILOTAGE_FEUX_POSITION_AVG
        data-element=AEELT_SWC.GERER_FX_POS.SIGNALER_S0.MDL_SIGNALER.SIGNALER.ECM_BODY_SWC.pp_CMD_FEUX_POSITION_AR.CMD_FEUX_POSITION_AR, signal=CMD_FEUX_POSITION_AR
        data-element=AEELT_SWC.GERER_FX_POS.SIGNALER_S0.MDL_SIGNALER.SIGNALER.ECM_BODY_SWC.pp_ETAT_FEUX_POSITION.ETAT_FEUX_POSITION, signal=ETAT_FEUX_POSITION
        data-element=AEELT_SWC.GERER_FX_POS.SIGNALER_S0.MDL_SIGNALER.SIGNALER.ECM_BODY_SWC.pp_P_TEM_SIGN_FX_POS.P_TEM_SIGN_FX_POS, signal=P_TEM_SIGN_FX_POS
        data-element=AEELT_SWC.GERER_FX_POS.SIGNALER_S0.MDL_SIGNALER.SIGNALER.ECM_BODY_SWC.pp_DMD_ALLUMAGE_FEUX_CROISEMENT.DMD_ALLUMAGE_FEUX_CROISEMENT, signal=DMD_ALLUMAGE_FEUX_CROISEMENT
        data-element=AEELT_SWC.DETERMINER_ETAT_PRODUCTION.GEE_PEE.MDL_GEE.GEE.ECM_BODY_SWC.pp_ETAT_GEN.ETAT_GEN, signal=ETAT_GEN
        data-element=AEELT_SWC.GID_S2.GID.SIGNALER_S2.MDL_SIGNALER.SIGNALER.ECM_BODY_SWC.pp_P_TEM_SIGN_FX_CLIGNO_G.P_TEM_SIGN_FX_CLIGNO_G, signal=P_TEM_SIGN_FX_CLIGNO_G
        data-element=AEELT_SWC.GID_S2.GID.SIGNALER_S2.MDL_SIGNALER.SIGNALER.ECM_BODY_SWC.pp_P_TEM_SIGN_FX_CLIGNO_D.P_TEM_SIGN_FX_CLIGNO_D, signal=P_TEM_SIGN_FX_CLIGNO_D
        data-element=AEELT_SWC.DETERMINER_ETAT_RESEAU_ELECTRIQUE_TI_TA.GEE_AQEB.MDL_GEE.GEE.ECM_BODY_SWC.rp_VITESSE_LONGITUDINALE.VITESSE_LONGITUDINALE, signal=VITESSE_LONGITUDINALE
        data-element=AEELT_SWC.DETERMINER_ETAT_RESEAU_ELECTRIQUE_TI_TA.GEE_AQEB.MDL_GEE.GEE.ECM_BODY_SWC.pp_ETAT_RESEAU_ELECTRIQUE.ETAT_RESEAU_ELECTRIQUE, signal=ETAT_RESEAU_ELECTRIQUE
        data-element=AEELT_SWC.DETERMINER_ETAT_RESEAU_ELECTRIQUE_TI_TA.GEE_AQEB.MDL_GEE.GEE.ECM_BODY_SWC.pp_MODE_ECO.MODE_ECO, signal=MODE_ECO
        data-element=AEELT_SWC.ECL_EXT_S0.MDL_SIGNALER.SIGNALER.ECM_BODY_SWC.rp_ETAT_COMMODO_ECLAIRAGE_4POS.ETAT_COMMODO_ECLAIRAGE_4POS, signal=ETAT_COMMODO_ECLAIRAGE_4POS
        data-element=AEELT_SWC.ECL_EXT_S0.MDL_SIGNALER.SIGNALER.ECM_BODY_SWC.pp_ETAT_CMD_ECLAIRAGE.ETAT_CMD_ECLAIRAGE, signal=ETAT_CMD_ECLAIRAGE
        data-element=AEELT_SWC.IHM_TRAME_CMD_BRT.MDL_IHM.IHM.ECM_BODY_SWC.rp_VITESSE_LONGITUDINALE.VITESSE_LONGITUDINALE, signal=VITESSE_LONGITUDINALE
        data-element=AEELT_SWC.IHM_TRAME_CMD_BRT.MDL_IHM.IHM.ECM_BODY_SWC.pp_EM_SON_CMD_BRT.EM_SON_CMD_BRT, signal=EM_SON_CMD_BRT
        data-element=AEELT_SWC.IHM_TRAME_CMD_BRT.MDL_IHM.IHM.ECM_BODY_SWC.pp_NIV_SON_CMD_BRT.NIV_SON_CMD_BRT, signal=NIV_SON_CMD_BRT
        data-element=AEELT_SWC.DETERMINER_INFO_GMP.GEE_SEE.MDL_GEE.GEE.ECM_BODY_SWC.rp_ETAT_MT.ETAT_MT, signal=ETAT_MT
        data-element=AEELT_SWC.DETERMINER_INFO_GMP.GEE_SEE.MDL_GEE.GEE.ECM_BODY_SWC.pp_ETAT_GMP.ETAT_GMP, signal=ETAT_GMP
        data-element=AEELT_SWC.GID_S1.GID.SIGNALER_S2.MDL_SIGNALER.SIGNALER.ECM_BODY_SWC.pp_ETAT_FEUX_DIRECTION.ETAT_FEUX_DIRECTION, signal=ETAT_FEUX_DIRECTION
        data-element=AEELT_SWC.GERER_PHASE_VIE_CAN_BODY.MDL_LPM_BODY.LPM.ECM_BODY_SWC.pp_PHASE_VIE.PHASE_VIE, signal=PHASE_VIE
        data-element=AEELT_SWC.GERER_PHASE_VIE_CAN_BODY.MDL_LPM_BODY.LPM.ECM_BODY_SWC.pp_ON_CMB.ON_CMB, signal=ON_CMB
        data-element=AEELT_SWC.VER_DEV_SPE.MDL_GAV.GAV.ECM_BODY_SWC.rp_VITESSE_LONGITUDINALE.VITESSE_LONGITUDINALE, signal=VITESSE_LONGITUDINALE
        data-element=AEELT_SWC.DETERMINER_ETAT_PRINCIP_SEV.GEE_SEE.MDL_GEE.GEE.ECM_BODY_SWC.rp_E_DEM.E_DEM, signal=E_DEM
        data-element=AEELT_SWC.DETERMINER_ETAT_PRINCIP_SEV.GEE_SEE.MDL_GEE.GEE.ECM_BODY_SWC.pp_ETAT_PRINCIP_SEV.ETAT_PRINCIP_SEV, signal=ETAT_PRINCIP_SEV
        data-element=AEELT_SWC.GERER_FX_STOP.SIGNALER_S1.MDL_SIGNALER.SIGNALER.ECM_BODY_SWC.rp_CONTACT_FREIN2.CONTACT_FREIN2, signal=CONTACT_FREIN2
        data-element=AEELT_SWC.GERER_FX_STOP.SIGNALER_S1.MDL_SIGNALER.SIGNALER.ECM_BODY_SWC.pp_CMD_FEUX_STOP.CMD_FEUX_STOP, signal=CMD_FEUX_STOP
        data-element=AEELT_SWC.PILOTER_SER.MDL_GAV.GAV.ECM_BODY_SWC.pp_CMD_SERR_MOT_EXT.CMD_SERR_MOT_EXT, signal=CMD_SERR_MOT_EXT
        data-element=AEELT_SWC.PILOTER_SER.MDL_GAV.GAV.ECM_BODY_SWC.pp_CMD_SERR_MOT_INT_AR.CMD_SERR_MOT_INT_AR, signal=CMD_SERR_MOT_INT_AR
        data-element=AEELT_SWC.PILOTER_SER.MDL_GAV.GAV.ECM_BODY_SWC.pp_CMD_SERR_MOT_INT_AV.CMD_SERR_MOT_INT_AV, signal=CMD_SERR_MOT_INT_AV
        data-element=AEELT_SWC.GERER_FX_MA.SIGNALER_S1.MDL_SIGNALER.SIGNALER.ECM_BODY_SWC.rp_ETAT_MA.ETAT_MA, signal=ETAT_MA
        data-element=AEELT_SWC.GERER_FX_MA.SIGNALER_S1.MDL_SIGNALER.SIGNALER.ECM_BODY_SWC.pp_CMD_FEUX_MAR.CMD_FEUX_MAR, signal=CMD_FEUX_MAR
        data-element=AEELT_SWC.TELECMD.MDL_GAV.GAV.ECM_BODY_SWC.pp_DMD_LOCAL_TELECMD.DMD_LOCAL_TELECMD, signal=DMD_LOCAL_TELECMD
        data-element=AEELT_SWC.GERER_ETAT_JOUR_NUIT.SIGNALER_S0.MDL_SIGNALER.SIGNALER.ECM_BODY_SWC.pp_ETAT_JOUR_NUIT.ETAT_JOUR_NUIT, signal=ETAT_JOUR_NUIT
        data-element=AEELT_SWC.GID_S0.GID.SIGNALER_S2.MDL_SIGNALER.SIGNALER.ECM_BODY_SWC.rp_ETAT_COMMODO_CLIGNO.ETAT_COMMODO_CLIGNO, signal=ETAT_COMMODO_CLIGNO
        data-element=AEELT_SWC.GID_S0.GID.SIGNALER_S2.MDL_SIGNALER.SIGNALER.ECM_BODY_SWC.rp_CHOC_FEUX_DET.CHOC_FEUX_DET, signal=CHOC_FEUX_DET
        data-element=AEELT_SWC.GID_S0.GID.SIGNALER_S2.MDL_SIGNALER.SIGNALER.ECM_BODY_SWC.rp_INFO_CHOC_PIETON.INFO_CHOC_PIETON, signal=INFO_CHOC_PIETON
        data-element=AEELT_SWC.GID_S0.GID.SIGNALER_S2.MDL_SIGNALER.SIGNALER.ECM_BODY_SWC.rp_VOLONTE_CONDUCTEUR.VOLONTE_CONDUCTEUR, signal=VOLONTE_CONDUCTEUR
        data-element=AEELT_SWC.GID_S0.GID.SIGNALER_S2.MDL_SIGNALER.SIGNALER.ECM_BODY_SWC.rp_DMD_WARNING_FORTE_DECEL.DMD_WARNING_FORTE_DECEL, signal=DMD_WARNING_FORTE_DECEL
        data-element=AEELT_SWC.GID_S0.GID.SIGNALER_S2.MDL_SIGNALER.SIGNALER.ECM_BODY_SWC.rp_FONCTION_SFU_DANS_UCFREIN.FNCT_SFU_UC_FREIN, signal=FNCT_SFU_UC_FREIN
        data-element=AEELT_SWC.GID_S0.GID.SIGNALER_S2.MDL_SIGNALER.SIGNALER.ECM_BODY_SWC.rp_VITESSE_LONGITUDINALE.VITESSE_LONGITUDINALE, signal=VITESSE_LONGITUDINALE
        data-element=AEELT_SWC.COMMANDER_ALIM_APC.GEE_SEE.MDL_GEE.GEE.ECM_BODY_SWC.pp_CDE_APC.CDE_APC, signal=CDE_APC
        data-element=AEELT_SWC.COMMANDER_ALIM_ACC.GEE_SEE.MDL_GEE.GEE.ECM_BODY_SWC.pp_CDE_ACC.CDE_ACC, signal=CDE_ACC
        data-element=AEELT_SWC.GERER_MAINTIEN_ECU.MDL_LPM_BODY.LPM.ECM_BODY_SWC.rp_E_HF.E_HF, signal=E_HF
        data-element=AEELT_SWC.GERER_MAINTIEN_ECU.MDL_LPM_BODY.LPM.ECM_BODY_SWC.rp_E_FEUX_POS.E_FEUX_POS, signal=E_FEUX_POS
        data-element=AEELT_SWC.GERER_MAINTIEN_ECU.MDL_LPM_BODY.LPM.ECM_BODY_SWC.rp_E_AVERTISSEUR.E_AVERTISSEUR, signal=E_AVERTISSEUR
        data-element=AEELT_SWC.GERER_MAINTIEN_ECU.MDL_LPM_BODY.LPM.ECM_BODY_SWC.rp_E_PHARE.E_PHARE, signal=E_PHARE
        data-element=AEELT_SWC.GERER_FX_ABAR.SIGNALER_S0.MDL_SIGNALER.SIGNALER.ECM_BODY_SWC.rp_DMD_ANTIBROUILLARD.DMD_ANTIBROUILLARD, signal=ETAT_DMD_ANTIBROUILLARD
        data-element=AEELT_SWC.GERER_FX_ABAR.SIGNALER_S0.MDL_SIGNALER.SIGNALER.ECM_BODY_SWC.rp_ETAT_FEUX_CROISEMENT.ETAT_FEUX_CROISEMENT, signal=ETAT_FEUX_CROISEMENT
        data-element=AEELT_SWC.GERER_FX_ABAR.SIGNALER_S0.MDL_SIGNALER.SIGNALER.ECM_BODY_SWC.rp_ETAT_FEUX_ROUTE.ETAT_FEUX_ROUTE, signal=ETAT_FEUX_ROUTE
        data-element=AEELT_SWC.GERER_FX_ABAR.SIGNALER_S0.MDL_SIGNALER.SIGNALER.ECM_BODY_SWC.rp_ETAT_ANTIBR_AV.ETAT_ANTIBR_AV, signal=ETAT_ANTIBR_AV
        data-element=AEELT_SWC.GERER_FX_ABAR.SIGNALER_S0.MDL_SIGNALER.SIGNALER.ECM_BODY_SWC.pp_CMD_ANTIBR_AR.CMD_ANTIBR_AR, signal=CMD_ANTIBR_AR
        data-element=AEELT_SWC.GERER_FX_ABAR.SIGNALER_S0.MDL_SIGNALER.SIGNALER.ECM_BODY_SWC.pp_ETAT_ANTIBR_AR.ETAT_ANTIBR_AR, signal=ETAT_ANTIBR_AR
        data-element=AEELT_SWC.GERER_FX_ABAR.SIGNALER_S0.MDL_SIGNALER.SIGNALER.ECM_BODY_SWC.pp_P_TEM_SIGN_FX_ABAR.P_TEM_SIGN_FX_ABAR, signal=P_TEM_SIGN_FX_ABAR
        data-element=AEELT_SWC.ECL_EXT_S1.MDL_SIGNALER.SIGNALER.ECM_BODY_SWC.pp_DMD_ANTIBROUILLARD.DMD_ANTIBROUILLARD, signal=DMD_ANTIBROUILLARD
        data-element=AEELT_SWC.ECL_EXT_S1.MDL_SIGNALER.SIGNALER.ECM_BODY_SWC.rp_ETAT_DMD_ANTIBROUILLARD.ETAT_DMD_ANTIBROUILLARD, signal=ETAT_DMD_ANTIBROUILLARD
      sw-mappings:
        swc to ecu mapping ECM_BODY: ecu-instance=ECM_BODY
          component:
            AEELT_SWC.SIGNALER_S1.MDL_SIGNALER.SIGNALER.ECM_BODY_SWC.GERER_AVER_SONORE
            AEELT_SWC.GEE_SEE.MDL_GEE.GEE.ECM_BODY_SWC.COMMANDER_ALIM_PLUS_CAN
            AEELT_SWC.SIGNALER_S0.MDL_SIGNALER.SIGNALER.ECM_BODY_SWC.GERER_FX_DIURNES
            AEELT_SWC.GEE_AQEB.MDL_GEE.GEE.ECM_BODY_SWC.CONVERTIR_TENSION_BATTERIE_UCFREIN
            AEELT_SWC.MDL_GAV.GAV.ECM_BODY_SWC.SECU_ENF
            AEELT_SWC.MDL_LPM_BODY.LPM.ECM_BODY_SWC.GERER_PHASE_VIE_CAN_IS
            AEELT_SWC.SIGNALER_S0.MDL_SIGNALER.SIGNALER.ECM_BODY_SWC.GERER_FX_POS
            AEELT_SWC.GEE_SEE.MDL_GEE.GEE.ECM_BODY_SWC.COMMANDER_ALIM_LOGIC_ECM_FRONT
            AEELT_SWC.GEE_PEE.MDL_GEE.GEE.ECM_BODY_SWC.DETERMINER_ETAT_PRODUCTION
            AEELT_SWC.GEE_AQEB.MDL_GEE.GEE.ECM_BODY_SWC.DETERMINER_ETAT_RESEAU_ELECTRIQUE_TA
            AEELT_SWC.GID.SIGNALER_S2.MDL_SIGNALER.SIGNALER.ECM_BODY_SWC.GID_S2
            AEELT_SWC.GEE_AQEB.MDL_GEE.GEE.ECM_BODY_SWC.DETERMINER_ETAT_RESEAU_ELECTRIQUE_TI
            AEELT_SWC.ECM_BODY_SWC.EcuM
            AEELT_SWC.SIGNALER_S2.MDL_SIGNALER.SIGNALER.ECM_BODY_SWC.GESD
            AEELT_SWC.ECM_BODY_SWC.IO_ASC
            AEELT_SWC.ECM_BODY_SWC.IOHWAB
            AEELT_SWC.MDL_SIGNALER.SIGNALER.ECM_BODY_SWC.SIGNALER_PARAM
            AEELT_SWC.GEE_AQEB.MDL_GEE.GEE.ECM_BODY_SWC.DETERMINER_ETAT_RESEAU_ELECTRIQUE_TI_TA
            AEELT_SWC.MDL_GAV.GAV.ECM_BODY_SWC.INFO_SER
            AEELT_SWC.MDL_IHM.IHM.ECM_BODY_SWC.IHM_OUBLI_FEUX
            AEELT_SWC.MDL_SIGNALER.SIGNALER.ECM_BODY_SWC.ECL_EXT_S0
            AEELT_SWC.GEE_AQEB.MDL_GEE.GEE.ECM_BODY_SWC.DETERMINER_COHERENCE_TENSION_BATTERIE
            AEELT_SWC.MDL_GAV.GAV.ECM_BODY_SWC.LED
            AEELT_SWC.MDL_IHM.IHM.ECM_BODY_SWC.IHM_TRAME_CMD_BRT
            AEELT_SWC.MDL_GAV.GAV.ECM_BODY_SWC.AUTO_VER_DEV
            AEELT_SWC.GEE_SEE.MDL_GEE.GEE.ECM_BODY_SWC.DETERMINER_INFO_GMP
            AEELT_SWC.GID.SIGNALER_S2.MDL_SIGNALER.SIGNALER.ECM_BODY_SWC.GID_S1
            AEELT_SWC.MDL_LPM_BODY.LPM.ECM_BODY_SWC.GERER_PHASE_VIE_CAN_BODY
            AEELT_SWC.MDL_GAV.GAV.ECM_BODY_SWC.VER_DEV_SPE
            AEELT_SWC.GEE_SEE.MDL_GEE.GEE.ECM_BODY_SWC.DETERMINER_ETAT_PRINCIP_SEV
            AEELT_SWC.GEE_AQEB.MDL_GEE.GEE.ECM_BODY_SWC.DETERMINER_CREDIT_TEMPS_TI_NOMINAL
            AEELT_SWC.SIGNALER_S1.MDL_SIGNALER.SIGNALER.ECM_BODY_SWC.GERER_FX_STOP
            AEELT_SWC.MDL_IHM.IHM.ECM_BODY_SWC.IHM_CLIGNO
            AEELT_SWC.MDL_SIGNALER.SIGNALER.ECM_BODY_SWC.ECL_EXT_S1
            AEELT_SWC.MDL_GAV.GAV.ECM_BODY_SWC.PILOTER_SER
            AEELT_SWC.SIGNALER_S1.MDL_SIGNALER.SIGNALER.ECM_BODY_SWC.GERER_FX_MA
            AEELT_SWC.MDL_GAV.GAV.ECM_BODY_SWC.TELECMD
            AEELT_SWC.SIGNALER_S0.MDL_SIGNALER.SIGNALER.ECM_BODY_SWC.GERER_ETAT_JOUR_NUIT
            AEELT_SWC.GID.SIGNALER_S2.MDL_SIGNALER.SIGNALER.ECM_BODY_SWC.GID_S0
            AEELT_SWC.ECM_BODY_SWC.ComM
            AEELT_SWC.GEE_SEE.MDL_GEE.GEE.ECM_BODY_SWC.COMMANDER_ALIM_APC
            AEELT_SWC.MDL_GAV.GAV.ECM_BODY_SWC.PUSH
            AEELT_SWC.GEE_SEE.MDL_GEE.GEE.ECM_BODY_SWC.COMMANDER_ALIM_ACC
            AEELT_SWC.ECM_BODY_SWC.MODE_MANAGER
            AEELT_SWC.MDL_LPM_BODY.LPM.ECM_BODY_SWC.GERER_PHASE_VIE_CAN_BACKBONE
            AEELT_SWC.MDL_LPM_BODY.LPM.ECM_BODY_SWC.GERER_MAINTIEN_ECU
            AEELT_SWC.SIGNALER_S0.MDL_SIGNALER.SIGNALER.ECM_BODY_SWC.GERER_FX_ABAR
            AEELT_SWC.GEE_AQEB.MDL_GEE.GEE.ECM_BODY_SWC.DETERMINER_TENSION_BATTERIE_PAR_TENSION_BSI
    software composition AEELT_SWC: software-composition=AEELT_SWC
  composition type AEELT_SWC
    component ECM_BODY_SWC: type=ECM_BODY_SWC
  composition type ECM_BODY_SWC
    10 x component:
      SIGNALER: type=SIGNALER
      GEE: type=GEE
      GAV: type=GAV
      LPM: type=LPM
      EcuM: type=EcuM
      IO_ASC: type=IO_ASC
      IOHWAB: type=IOHWAB
      IHM: type=IHM
      ComM: type=ComM
      MODE_MANAGER: type=MODE_MANAGER
    connect EcuM.SR000 -> MODE_MANAGER.rp_EcuM_StateRequest
    connect EcuM.currentMode -> MODE_MANAGER.rp_EcM_CurrentMode
    connect IOHWAB.pp_IOHWAB -> IO_ASC.rp_IOHWAB
    connect MODE_MANAGER.pp_CDE_PLUS_CAN -> IO_ASC.rp_CDE_PLUS_CAN
    connect MODE_MANAGER.pp_S_CDE_CPC_BODY_RELAY -> IO_ASC.rp_S_CDE_CPC_BODY_RELAY
    connect MODE_MANAGER.pp_CDE_LOGIC_ECM_FRONT -> IO_ASC.rp_CDE_LOGIC_ECM_FRONT
    connect ComM.UR000 -> MODE_MANAGER.rp_ComMUserRequest0
    connect ComM.UM000 -> MODE_MANAGER.rp_ComM_CurrentMode
    connect ComM.UR001 -> MODE_MANAGER.rp_ComMUserRequest1
    connect GEE.pp_ETAT_PRINCIP_SEV -> SIGNALER.rp_ETAT_PRINCIP_SEV
    connect GEE.pp_ETAT_RESEAU_ELECTRIQUE -> SIGNALER.rp_ETAT_RESEAU_ELECTRIQUE
    connect GEE.pp_CDE_APC -> SIGNALER.rp_CDE_APC
    connect GAV.pp_DMD_LOCAL_TELECMD -> SIGNALER.rp_DMD_LOCAL_TELECMD
    connect GAV.pp_ETAT_CPO_COND -> SIGNALER.rp_ETAT_CPO_COND
    connect GAV.pp_ETAT_CONDA -> SIGNALER.rp_ETAT_CONDA
    connect GAV.pp_TYPE_CONDA -> SIGNALER.rp_TYPE_CONDA
    connect SIGNALER.pp_ETAT_FEUX_DETRESSE -> LPM.rp_ETAT_FEUX_DETRESSE
    connect SIGNALER.pp_ETAT_FEUX_DIURNES -> LPM.rp_ETAT_FEUX_DIURNES
    connect SIGNALER.pp_ETAT_FEUX_POSITION -> LPM.rp_ETAT_FEUX_POSITION
    connect SIGNALER.pp_CMD_AVER_SONORE -> LPM.rp_CMD_AVER_SONORE
    connect IO_ASC.pp_APPUI_PEDALE_FREIN -> SIGNALER.rp_APPUI_PEDALE_FREIN
    connect IO_ASC.pp_DMD_FEUX_DETRESSE -> SIGNALER.rp_DMD_FEUX_DETRESSE
    connect IO_ASC.pp_DIAG_CLIGNO_AVD -> SIGNALER.rp_DIAG_CLIGNO_AVD
    connect IO_ASC.pp_DIAG_CLIGNO_ARD -> SIGNALER.rp_DIAG_CLIGNO_ARD
    connect IO_ASC.pp_DIAG_CLIGNO_AVG -> SIGNALER.rp_DIAG_CLIGNO_AVG
    connect IO_ASC.pp_DIAG_CLIGNO_ARG -> SIGNALER.rp_DIAG_CLIGNO_ARG
    connect SIGNALER.pp_PILOTAGE_CLIGNO_AVG -> IO_ASC.rp_PILOTAGE_CLIGNO_AVG
    connect SIGNALER.pp_PILOTAGE_CLIGNO_AVD -> IO_ASC.rp_PILOTAGE_CLIGNO_AVD
    connect SIGNALER.pp_P_LED_SIGN_PUSH_FEU_DET -> IO_ASC.rp_P_LED_SIGN_PUSH_FEU_DET
    connect SIGNALER.pp_CMD_CLIGNO_ARG -> IO_ASC.rp_CMD_CLIGNO_ARG
    connect SIGNALER.pp_CMD_CLIGNO_ARD -> IO_ASC.rp_CMD_CLIGNO_ARD
    connect SIGNALER.pp_ETAT_CLIGNOTANT_G -> IHM.rp_ETAT_CLIGNOTANT_G
    connect SIGNALER.pp_ETAT_CLIGNOTANT_D -> IHM.rp_ETAT_CLIGNOTANT_D
    connect SIGNALER.pp_P_SON_SIGN_FX_CLIGNO_CLIC -> IHM.rp_P_SON_SIGN_FX_CLIGNO_CLIC
    connect SIGNALER.pp_P_SON_SIGN_FX_CLIGNO_CLAC -> IHM.rp_P_SON_SIGN_FX_CLIGNO_CLAC
    connect SIGNALER.pp_P_SON_SIGN_FX_CLIGNO_CLIC_R -> IHM.rp_P_SON_SIGN_FX_CLIGNO_CLIC_R
    connect SIGNALER.pp_P_SON_SIGN_FX_CLIGNO_CLAC_R -> IHM.rp_P_SON_SIGN_FX_CLIGNO_CLAC_R
    connect SIGNALER.pp_P_SON_SIGN_FX_CLIGNO_CLIC_REL -> IHM.rp_P_SON_SIGN_FX_CLIGNO_CLIC_REL
    connect SIGNALER.pp_P_SON_SIGN_FX_CLIGNO_CLAC_REL -> IHM.rp_P_SON_SIGN_FX_CLIGNO_CLAC_REL
    connect SIGNALER.pp_P_SON_SIGN_FX_CLIGNO_CLIC_R_REL -> IHM.rp_P_SON_SIGN_FX_CLIGNO_CLIC_R_REL
    connect SIGNALER.pp_P_SON_SIGN_FX_CLIGNO_CLAC_R_REL -> IHM.rp_P_SON_SIGN_FX_CLIGNO_CLAC_R_REL
    connect SIGNALER.pp_P_SON_SIGN_OUBLI_FEUX -> IHM.rp_P_SON_SIGN_OUBLI_FEUX
    connect GEE.pp_ETAT_PRINCIP_SEV -> GAV.rp_ETAT_PRINCIP_SEV
    connect GEE.pp_INFO_GMP -> GAV.rp_INFO_GMP
    connect LPM.pp_PHASE_VIE -> GEE.rp_PHASE_VIE
    connect LPM.pp_CAN_BACKBONE_ACTIVITY -> GEE.rp_CAN_BACKBONE_ACTIVITY
    connect GEE.pp_ETAT_PRINCIP_SEV -> LPM.rp_ETAT_PRINCIP_SEV
    connect GEE.pp_CDE_APC -> LPM.rp_CDE_APC
    connect IO_ASC.pp_E_APC -> GEE.rp_E_APC
    connect IO_ASC.pp_U_BAT -> GEE.rp_U_BAT
    connect GEE.pp_CDE_LOGIC_ECM_FRONT -> IO_ASC.rp_CDE_LOGIC_ECM_FRONT
    connect GEE.pp_CDE_PLUS_CAN -> IO_ASC.rp_CDE_PLUS_CAN
    connect GAV.pp_P_LED_GAV_ETAT_VERR_CENT -> IO_ASC.rp_P_LED_GAV_ETAT_VERR_CENT
    connect GAV.pp_P_LED_GAV_ETAT_SECU_ENF -> IO_ASC.rp_P_LED_GAV_ETAT_SECU_ENF
    connect GAV.pp_CMD_SERR_MOT_COMMUN -> IO_ASC.rp_CMD_SERR_MOT_COMMUN
    connect IO_ASC.pp_INFO_CPO_ARG -> GAV.rp_INFO_CPO_ARG
    connect IO_ASC.pp_INFO_CPO_AVG -> GAV.rp_INFO_CPO_AVG
    connect IO_ASC.pp_INFO_CAV_AVG -> GAV.rp_INFO_CAV_AVG
    connect IO_ASC.pp_DMPD_GAV_SECU_ENFANT -> GAV.rp_DMDP_GAV_SECU_ENFANT
    connect IO_ASC.pp_DMDP_GAV_VERR_CENTRALISE -> GAV.rp_DMDP_GAV_VERR_CENTRALISE
    connect LPM.pp_ECU_ACTIVITY -> MODE_MANAGER.ECU_ACTIVITY
    connect LPM.pp_CAN_BODY_ACTIVITY -> MODE_MANAGER.CAN_BODY_ACTIVITY
    connect LPM.pp_CAN_BACKBONE_ACTIVITY -> MODE_MANAGER.CAN_BACKBONE_ACTIVITY
    connect LPM.pp_CAN_IS_ACTIVITY -> MODE_MANAGER.CAN_IS_ACTIVITY
  5 x i pdu group:
    IPDUGroupIN_CAN_HS_BACKBONE: communication-direction=IN, i-pdu=[ipdu_BB_FRONT_200, ipdu_BB_FRONT_201]
    IPDUGroupOUT_CAN_HS_BACKBONE: communication-direction=OUT, i-pdu=[ipdu_BB_BODY_432, ipdu_BB_BODY_101, ipdu_BB_BODY_100]
    IPDUGroupIN_CAN_LS_BODY: communication-direction=IN, i-pdu=[ipdu_REVEIL_HDC, ipdu_ETAT_BDCP, ipdu_ETAT_CDPL_RAPIDES, ipdu_ETAT_HDC]
    IPDUGroupOUT_CAN_LS_BODY: communication-direction=OUT, i-pdu=[ipdu_DONNEES_BSI_RAPIDES, ipdu_DONNEES_BSI_LENTES, ipdu_COMMANDE_BRT, ipdu_LS_BODY_36, ipdu_CDE_CMB_SIGNALISATION]
    IPDUGroupOUT_LIN_UPE_BODY: communication-direction=OUT, i-pdu=ipdu_UPE_BODY_19
  ecu sw composition EcuSwComposition: ecu-extract=AEELT
